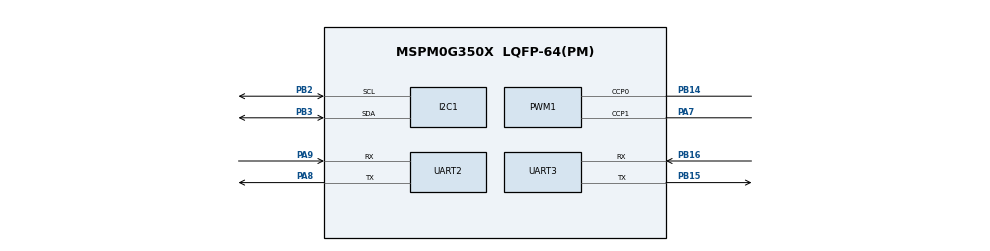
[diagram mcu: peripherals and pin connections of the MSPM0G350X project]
/**
 * @cliArgs --device "MSPM0G350X" --part "Default" --package "LQFP-64(PM)" --product "mspm0_sdk@2.11.00.07"
 * @versions {"tool":"1.26.2+4477"}
 */

/**
 * Import the modules used in this configuration.
 */
const GPIO   = scripting.addModule("/ti/driverlib/GPIO", {}, false);
const GPIO1  = GPIO.addInstance();
const GPIO2  = GPIO.addInstance();
const GPIO3  = GPIO.addInstance();
const GPIO4  = GPIO.addInstance();
const GPIO5  = GPIO.addInstance();
const GPIO6  = GPIO.addInstance();
const GPIO7  = GPIO.addInstance();
const I2C    = scripting.addModule("/ti/driverlib/I2C", {}, false);
const I2C1   = I2C.addInstance();
const PWM    = scripting.addModule("/ti/driverlib/PWM", {}, false);
const PWM1   = PWM.addInstance();
const SYSCTL = scripting.addModule("/ti/driverlib/SYSCTL");
const TIMER  = scripting.addModule("/ti/driverlib/TIMER", {}, false);
const TIMER1 = TIMER.addInstance();
const UART   = scripting.addModule("/ti/driverlib/UART", {}, false);
const UART1  = UART.addInstance();
const UART2  = UART.addInstance();
const UART3  = UART.addInstance();

/**
 * Write custom configuration values to the imported modules.
 */
const divider7       = system.clockTree["PLL_PDIV"];
divider7.divideValue = 2;

const divider9       = system.clockTree["UDIV"];
divider9.divideValue = 2;

const gate7  = system.clockTree["MFCLKGATE"];
gate7.enable = true;

const multiplier2         = system.clockTree["PLL_QDIV"];
multiplier2.multiplyValue = 5;

const mux8       = system.clockTree["HSCLKMUX"];
mux8.inputSelect = "HSCLKMUX_SYSPLL2X";

GPIO1.$name                          = "GPIO_OLED";
GPIO1.associatedPins.create(2);
GPIO1.associatedPins[0].$name        = "PIN_OLED_SCL";
GPIO1.associatedPins[0].assignedPort = "PORTA";
GPIO1.associatedPins[0].assignedPin  = "1";
GPIO1.associatedPins[1].$name        = "PIN_OLED_SDA";
GPIO1.associatedPins[1].assignedPort = "PORTA";
GPIO1.associatedPins[1].assignedPin  = "0";

const Board = scripting.addModule("/ti/driverlib/Board", {}, false);

GPIO2.$name                          = "tb6612";
GPIO2.associatedPins.create(4);
GPIO2.associatedPins[0].$name        = "BIN1";
GPIO2.associatedPins[0].assignedPort = "PORTB";
GPIO2.associatedPins[0].assignedPin  = "7";
GPIO2.associatedPins[1].$name        = "BIN2";
GPIO2.associatedPins[1].assignedPort = "PORTB";
GPIO2.associatedPins[1].assignedPin  = "6";
GPIO2.associatedPins[2].$name        = "AIN1";
GPIO2.associatedPins[2].assignedPort = "PORTB";
GPIO2.associatedPins[2].assignedPin  = "9";
GPIO2.associatedPins[3].$name        = "AIN2";
GPIO2.associatedPins[3].assignedPort = "PORTB";
GPIO2.associatedPins[3].assignedPin  = "10";

GPIO3.$name                               = "encoder_L";
GPIO3.associatedPins.create(2);
GPIO3.associatedPins[0].$name             = "PB26";
GPIO3.associatedPins[0].direction         = "INPUT";
GPIO3.associatedPins[0].assignedPort      = "PORTB";
GPIO3.associatedPins[0].assignedPin       = "26";
GPIO3.associatedPins[0].interruptEn       = true;
GPIO3.associatedPins[0].interruptPriority = "0";
GPIO3.associatedPins[0].polarity          = "RISE";
GPIO3.associatedPins[1].$name             = "PA13";
GPIO3.associatedPins[1].assignedPort      = "PORTA";
GPIO3.associatedPins[1].assignedPin       = "13";
GPIO3.associatedPins[1].direction         = "INPUT";
GPIO3.associatedPins[1].polarity          = "RISE";
GPIO3.associatedPins[1].interruptEn       = true;
GPIO3.associatedPins[1].interruptPriority = "0";

GPIO4.$name                               = "encoder_R";
GPIO4.associatedPins.create(2);
GPIO4.associatedPins[0].$name             = "PB5";
GPIO4.associatedPins[0].assignedPort      = "PORTB";
GPIO4.associatedPins[0].assignedPin       = "5";
GPIO4.associatedPins[0].direction         = "INPUT";
GPIO4.associatedPins[0].interruptEn       = true;
GPIO4.associatedPins[0].interruptPriority = "0";
GPIO4.associatedPins[0].polarity          = "RISE";
GPIO4.associatedPins[1].$name             = "PB4";
GPIO4.associatedPins[1].assignedPort      = "PORTB";
GPIO4.associatedPins[1].assignedPin       = "4";
GPIO4.associatedPins[1].direction         = "INPUT";
GPIO4.associatedPins[1].interruptEn       = true;
GPIO4.associatedPins[1].interruptPriority = "0";
GPIO4.associatedPins[1].polarity          = "RISE";

GPIO5.$name                              = "key";
GPIO5.associatedPins.create(2);
GPIO5.associatedPins[0].assignedPort     = "PORTB";
GPIO5.associatedPins[0].assignedPin      = "23";
GPIO5.associatedPins[0].$name            = "KEY1";
GPIO5.associatedPins[0].direction        = "INPUT";
GPIO5.associatedPins[0].internalResistor = "PULL_UP";
GPIO5.associatedPins[1].$name            = "KEY2";
GPIO5.associatedPins[1].direction        = "INPUT";
GPIO5.associatedPins[1].assignedPort     = "PORTB";
GPIO5.associatedPins[1].assignedPin      = "27";
GPIO5.associatedPins[1].internalResistor = "PULL_UP";

GPIO6.$name                          = "redlight";
GPIO6.associatedPins.create(8);
GPIO6.associatedPins[0].$name        = "PIN_0";
GPIO6.associatedPins[0].assignedPort = "PORTB";
GPIO6.associatedPins[0].assignedPin  = "19";
GPIO6.associatedPins[0].direction    = "INPUT";
GPIO6.associatedPins[1].$name        = "PIN_1";
GPIO6.associatedPins[1].direction    = "INPUT";
GPIO6.associatedPins[1].assignedPort = "PORTB";
GPIO6.associatedPins[1].assignedPin  = "17";
GPIO6.associatedPins[2].$name        = "PIN_2";
GPIO6.associatedPins[2].direction    = "INPUT";
GPIO6.associatedPins[2].assignedPort = "PORTA";
GPIO6.associatedPins[2].assignedPin  = "16";
GPIO6.associatedPins[3].$name        = "PIN_3";
GPIO6.associatedPins[3].direction    = "INPUT";
GPIO6.associatedPins[3].assignedPort = "PORTA";
GPIO6.associatedPins[3].assignedPin  = "14";
GPIO6.associatedPins[4].$name        = "PIN_4";
GPIO6.associatedPins[4].assignedPort = "PORTB";
GPIO6.associatedPins[4].assignedPin  = "20";
GPIO6.associatedPins[4].direction    = "INPUT";
GPIO6.associatedPins[5].$name        = "PIN_5";
GPIO6.associatedPins[5].assignedPort = "PORTB";
GPIO6.associatedPins[5].assignedPin  = "25";
GPIO6.associatedPins[5].direction    = "INPUT";
GPIO6.associatedPins[6].$name        = "PIN_6";
GPIO6.associatedPins[6].assignedPort = "PORTA";
GPIO6.associatedPins[6].assignedPin  = "25";
GPIO6.associatedPins[6].direction    = "INPUT";
GPIO6.associatedPins[7].$name        = "PIN_7";
GPIO6.associatedPins[7].assignedPort = "PORTA";
GPIO6.associatedPins[7].assignedPin  = "27";
GPIO6.associatedPins[7].direction    = "INPUT";

GPIO7.$name                         = "buzzer";
GPIO7.port                          = "PORTA";
GPIO7.associatedPins[0].$name       = "control";
GPIO7.associatedPins[0].assignedPin = "29";
GPIO7.associatedPins[0].ioStructure = "SD";

I2C1.$name                             = "I2C_BNO08X";
I2C1.basicEnableController             = true;
I2C1.peripheral.$assign                = "I2C1";
I2C1.peripheral.sdaPin.$assign         = "PB3";
I2C1.peripheral.sclPin.$assign         = "PB2";
I2C1.sdaPinConfig.hideOutputInversion  = scripting.forceWrite(false);
I2C1.sdaPinConfig.onlyInternalResistor = scripting.forceWrite(false);
I2C1.sdaPinConfig.passedPeripheralType = scripting.forceWrite("Digital");
I2C1.sdaPinConfig.$name                = "ti_driverlib_gpio_GPIOPinGeneric1";
I2C1.sclPinConfig.hideOutputInversion  = scripting.forceWrite(false);
I2C1.sclPinConfig.onlyInternalResistor = scripting.forceWrite(false);
I2C1.sclPinConfig.passedPeripheralType = scripting.forceWrite("Digital");
I2C1.sclPinConfig.$name                = "ti_driverlib_gpio_GPIOPinGeneric9";

PWM1.timerStartTimer                    = true;
PWM1.$name                              = "PWM_tb6612";
PWM1.clockDivider                       = 8;
PWM1.peripheral.$assign                 = "TIMA0";
PWM1.peripheral.ccp0Pin.$assign         = "PB14";
PWM1.peripheral.ccp1Pin.$assign         = "PA7";
PWM1.PWM_CHANNEL_0.$name                = "ti_driverlib_pwm_PWMTimerCC0";
PWM1.PWM_CHANNEL_0.invert               = true;
PWM1.PWM_CHANNEL_1.$name                = "ti_driverlib_pwm_PWMTimerCC1";
PWM1.PWM_CHANNEL_1.invert               = true;
PWM1.ccp0PinConfig.direction            = scripting.forceWrite("OUTPUT");
PWM1.ccp0PinConfig.hideOutputInversion  = scripting.forceWrite(false);
PWM1.ccp0PinConfig.onlyInternalResistor = scripting.forceWrite(false);
PWM1.ccp0PinConfig.passedPeripheralType = scripting.forceWrite("Digital");
PWM1.ccp0PinConfig.$name                = "ti_driverlib_gpio_GPIOPinGeneric0";
PWM1.ccp1PinConfig.direction            = scripting.forceWrite("OUTPUT");
PWM1.ccp1PinConfig.hideOutputInversion  = scripting.forceWrite(false);
PWM1.ccp1PinConfig.onlyInternalResistor = scripting.forceWrite(false);
PWM1.ccp1PinConfig.passedPeripheralType = scripting.forceWrite("Digital");
PWM1.ccp1PinConfig.$name                = "ti_driverlib_gpio_GPIOPinGeneric2";

SYSCTL.forceDefaultClkConfig = true;
SYSCTL.clockTreeEn           = true;

TIMER1.$name             = "TIMER_TICK";
TIMER1.timerMode         = "PERIODIC";
TIMER1.timerStartTimer   = true;
TIMER1.interrupts        = ["ZERO"];
TIMER1.interruptPriority = "3";
TIMER1.timerClkDiv       = 8;
TIMER1.timerClkPrescale  = 80;
TIMER1.timerPeriod       = "50ms";

UART1.$name             = "UART_0";
UART1.enabledInterrupts = ["RX"];
UART1.uartClkSrc        = "MFCLK";
UART1.interruptPriority = "2";
UART1.txPinConfig.$name = "ti_driverlib_gpio_GPIOPinGeneric3";
UART1.rxPinConfig.$name = "ti_driverlib_gpio_GPIOPinGeneric4";

UART2.$name                    = "UART_1";
UART2.targetBaudRate           = 115200;
UART2.enabledInterrupts        = ["RX"];
UART2.uartClkSrc               = "MFCLK";
UART2.interruptPriority        = "0";
UART2.peripheral.$assign       = "UART1";
UART2.peripheral.rxPin.$assign = "PA9";
UART2.peripheral.txPin.$assign = "PA8";
UART2.txPinConfig.$name        = "ti_driverlib_gpio_GPIOPinGeneric7";
UART2.rxPinConfig.$name        = "ti_driverlib_gpio_GPIOPinGeneric8";

UART3.$name                            = "UART_WIT";
UART3.targetBaudRate                   = 115200;
UART3.enableFIFO                       = true;
UART3.rxTimeoutValue                   = 1;
UART3.enabledInterrupts                = ["RX_TIMEOUT_ERROR"];
UART3.enabledDMARXTriggers             = "DL_UART_DMA_INTERRUPT_RX";
UART3.interruptPriority                = "3";
UART3.peripheral.$assign               = "UART2";
UART3.peripheral.rxPin.$assign         = "PB16";
UART3.peripheral.txPin.$assign         = "PB15";
UART3.txPinConfig.direction            = scripting.forceWrite("OUTPUT");
UART3.txPinConfig.hideOutputInversion  = scripting.forceWrite(false);
UART3.txPinConfig.onlyInternalResistor = scripting.forceWrite(false);
UART3.txPinConfig.passedPeripheralType = scripting.forceWrite("Digital");
UART3.txPinConfig.$name                = "ti_driverlib_gpio_GPIOPinGeneric13";
UART3.rxPinConfig.hideOutputInversion  = scripting.forceWrite(false);
UART3.rxPinConfig.onlyInternalResistor = scripting.forceWrite(false);
UART3.rxPinConfig.passedPeripheralType = scripting.forceWrite("Digital");
UART3.rxPinConfig.$name                = "ti_driverlib_gpio_GPIOPinGeneric12";
UART3.DMA_CHANNEL_RX.$name             = "DMA_WIT";
UART3.DMA_CHANNEL_RX.addressMode       = "f2b";
UART3.DMA_CHANNEL_RX.srcLength         = "BYTE";
UART3.DMA_CHANNEL_RX.dstLength         = "BYTE";

/**
 * Pinmux solution for unlocked pins/peripherals. This ensures that minor changes to the automatic solver in a future
 * version of the tool will not impact the pinmux you originally saw.  These lines can be completely deleted in order to
 * re-solve from scratch.
 */
GPIO1.associatedPins[0].pin.$suggestSolution     = "PA1";
GPIO1.associatedPins[1].pin.$suggestSolution     = "PA0";
Board.peripheral.$suggestSolution                = "DEBUGSS";
Board.peripheral.swclkPin.$suggestSolution       = "PA20";
Board.peripheral.swdioPin.$suggestSolution       = "PA19";
GPIO2.associatedPins[0].pin.$suggestSolution     = "PB7";
GPIO2.associatedPins[1].pin.$suggestSolution     = "PB6";
GPIO2.associatedPins[2].pin.$suggestSolution     = "PB9";
GPIO2.associatedPins[3].pin.$suggestSolution     = "PB10";
GPIO3.associatedPins[0].pin.$suggestSolution     = "PB26";
GPIO3.associatedPins[1].pin.$suggestSolution     = "PA13";
GPIO4.associatedPins[0].pin.$suggestSolution     = "PB5";
GPIO4.associatedPins[1].pin.$suggestSolution     = "PB4";
GPIO5.associatedPins[0].pin.$suggestSolution     = "PB23";
GPIO5.associatedPins[1].pin.$suggestSolution     = "PB27";
GPIO6.associatedPins[0].pin.$suggestSolution     = "PB19";
GPIO6.associatedPins[1].pin.$suggestSolution     = "PB17";
GPIO6.associatedPins[2].pin.$suggestSolution     = "PA16";
GPIO6.associatedPins[3].pin.$suggestSolution     = "PA14";
GPIO6.associatedPins[4].pin.$suggestSolution     = "PB20";
GPIO6.associatedPins[5].pin.$suggestSolution     = "PB25";
GPIO6.associatedPins[6].pin.$suggestSolution     = "PA25";
GPIO6.associatedPins[7].pin.$suggestSolution     = "PA27";
GPIO7.associatedPins[0].pin.$suggestSolution     = "PA29";
TIMER1.peripheral.$suggestSolution               = "TIMA1";
UART1.peripheral.$suggestSolution                = "UART0";
UART1.peripheral.rxPin.$suggestSolution          = "PA11";
UART1.peripheral.txPin.$suggestSolution          = "PA10";
UART3.DMA_CHANNEL_RX.peripheral.$suggestSolution = "DMA_CH0";
